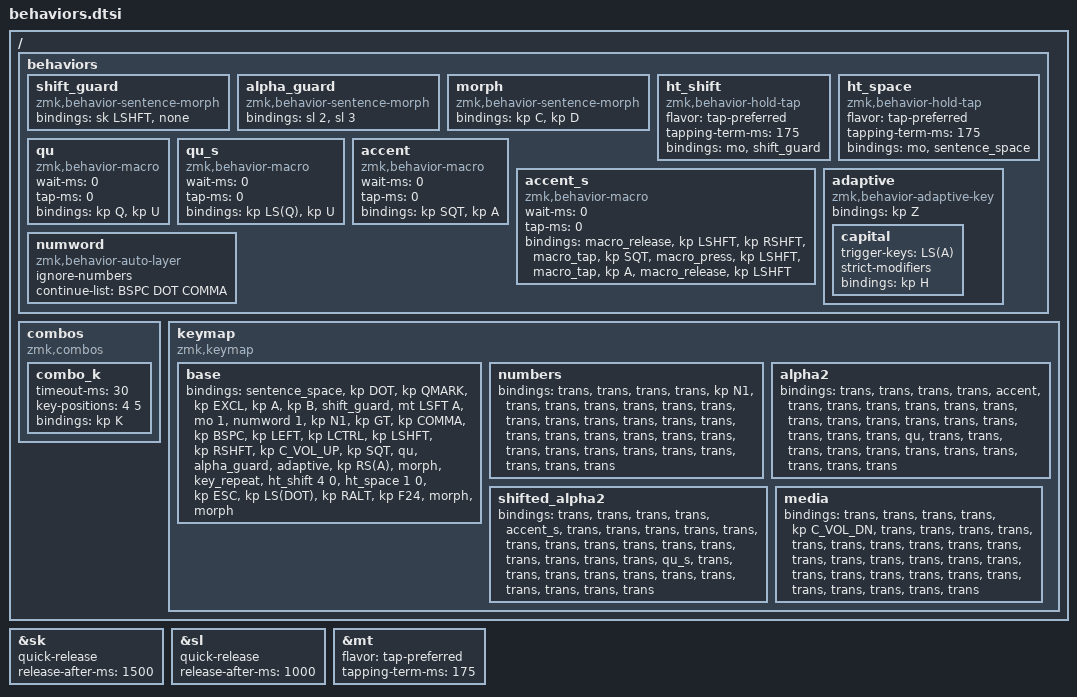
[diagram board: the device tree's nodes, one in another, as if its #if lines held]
#include <behaviors.dtsi>
#include <behaviors/sentence_case.dtsi>
#include <dt-bindings/zmk/keys.h>
#include <dt-bindings/zmk/kscan_mock.h>

&sk { quick-release; release-after-ms = <1500>; };
&sl { quick-release; release-after-ms = <1000>; };
&mt { flavor = "tap-preferred"; tapping-term-ms = <175>; };

/ {
    behaviors {
        shift_guard: shift_guard {
            compatible = "zmk,behavior-sentence-morph";
            #binding-cells = <0>;
            bindings = <&sk LSHFT>, <&none>;
        };
        alpha_guard: alpha_guard {
            compatible = "zmk,behavior-sentence-morph";
            #binding-cells = <0>;
            bindings = <&sl 2>, <&sl 3>;
        };
        morph: morph {
            compatible = "zmk,behavior-sentence-morph";
            #binding-cells = <0>;
            bindings = <&kp C>, <&kp D>;
        };
        ht_shift: ht_shift {
            compatible = "zmk,behavior-hold-tap";
            #binding-cells = <2>;
            flavor = "tap-preferred";
            tapping-term-ms = <175>;
            bindings = <&mo>, <&shift_guard>;
        };
        ht_space: ht_space {
            compatible = "zmk,behavior-hold-tap";
            #binding-cells = <2>;
            flavor = "tap-preferred";
            tapping-term-ms = <175>;
            bindings = <&mo>, <&sentence_space>;
        };
        qu: qu {
            compatible = "zmk,behavior-macro";
            #binding-cells = <0>;
            wait-ms = <0>; tap-ms = <0>;
            bindings = <&kp Q &kp U>;
        };
        qu_s: qu_s {
            compatible = "zmk,behavior-macro";
            #binding-cells = <0>;
            wait-ms = <0>; tap-ms = <0>;
            bindings = <&kp LS(Q) &kp U>;
        };
        accent: accent {
            compatible = "zmk,behavior-macro";
            #binding-cells = <0>;
            wait-ms = <0>; tap-ms = <0>;
            bindings = <&kp SQT &kp A>;
        };
        accent_s: accent_s {
            compatible = "zmk,behavior-macro";
            #binding-cells = <0>;
            wait-ms = <0>; tap-ms = <0>;
            // Same shift/dead-key ordering as the keymap's ACCENT(..._s).
            bindings = <&macro_release &kp LSHFT &kp RSHFT &macro_tap &kp SQT
                        &macro_press &kp LSHFT &macro_tap &kp A &macro_release &kp LSHFT>;
        };
#ifdef SENTENCE_TEST_ADAPTIVE
        adaptive: adaptive {
            compatible = "zmk,behavior-adaptive-key";
            #binding-cells = <0>;
            bindings = <&kp Z>;
            capital {
                trigger-keys = <LS(A)>;
                strict-modifiers;
                bindings = <&kp H>;
            };
        };
#endif
#ifdef SENTENCE_TEST_AUTO_LAYER
        numword: numword {
            compatible = "zmk,behavior-auto-layer";
            #binding-cells = <1>;
            ignore-numbers;
            continue-list = <BSPC DOT COMMA>;
        };
#endif
    };
    combos {
        compatible = "zmk,combos";
        combo_k {
            timeout-ms = <30>;
            key-positions = <4 5>;
            bindings = <&kp K>;
        };
    };
    keymap {
        compatible = "zmk,keymap";
        base {
            bindings = <
                &sentence_space &kp DOT &kp QMARK &kp EXCL
                &kp A &kp B &shift_guard &mt LSFT A
                &mo 1
#ifdef SENTENCE_TEST_AUTO_LAYER
                &numword 1
#else
                &sk LSHFT
#endif
                &kp N1 &kp GT
                &kp COMMA &kp BSPC &kp LEFT &kp LCTRL
                &kp LSHFT &kp RSHFT &kp C_VOL_UP &kp SQT
                &qu &alpha_guard
#ifdef SENTENCE_TEST_ADAPTIVE
                &adaptive
#else
                &kp K
#endif
                &kp RS(A)
                &morph &key_repeat &ht_shift 4 0 &ht_space 1 0
                &kp ESC &kp LS(DOT) &kp RALT &kp F24
                &morph &morph
            >;
        };
        numbers {
            bindings = <
                &trans &trans &trans &trans &kp N1 &trans &trans &trans
                &trans &trans &trans &trans &trans &trans &trans &trans
                &trans &trans &trans &trans &trans &trans &trans &trans
                &trans &trans &trans &trans &trans &trans &trans &trans
            >;
        };
        alpha2 {
            bindings = <
                &trans &trans &trans &trans &accent &trans &trans &trans
                &trans &trans &trans &trans &trans &trans &trans &trans
                &trans &trans &trans &trans &qu &trans &trans &trans
                &trans &trans &trans &trans &trans &trans &trans &trans
            >;
        };
        shifted_alpha2 {
            bindings = <
                &trans &trans &trans &trans &accent_s &trans &trans &trans
                &trans &trans &trans &trans &trans &trans &trans &trans
                &trans &trans &trans &trans &qu_s &trans &trans &trans
                &trans &trans &trans &trans &trans &trans &trans &trans
            >;
        };
        media {
            bindings = <
                &trans &trans &trans &trans &kp C_VOL_DN &trans &trans &trans
                &trans &trans &trans &trans &trans &trans &trans &trans
                &trans &trans &trans &trans &trans &trans &trans &trans
                &trans &trans &trans &trans &trans &trans &trans &trans
            >;
        };
    };
};
